# MSPM0G110X register map
Vendor: Texas Instruments; File version: This preliminary header file does not have a version number - build date: 2023-02-21 16:25:48
CPU: CM0 r0p1, little endian, MPU, no FPU, 3 interrupt priority bits
Registers are 32-bit, read-write, reset 0x0 unless marked. A register's access mark holds for its fields unless they carry their own. Offsets are from the block's base; [hi:lo] are bit positions; {n}, {i} and the like mark numbered series.

## CPUSS — CPUSSMMR
Base 0x40400000
0x10E0 EVT_MODE ro — Event Mode
  [1:0] EVT_MODE_INT_CFG — Event line mode select
    0=EVT_MODE_INT_CFG_DISABLE (DISABLE); 1=EVT_MODE_INT_CFG_SOFTWARE (SOFTWARE); 2=EVT_MODE_INT_CFG_HARDWARE (HARDWARE)
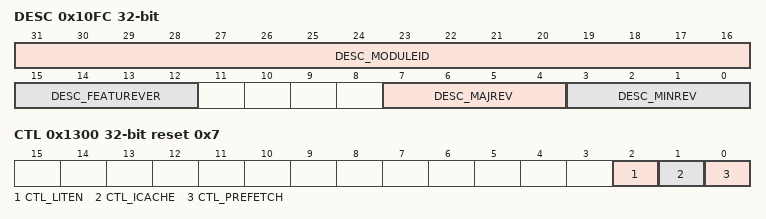
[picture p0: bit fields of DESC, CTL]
0x10FC DESC ro — Module Description
  [31:16] DESC_MODULEID — Module identification contains a unique peripheral identification number. The assignments are maintained in a central database for all of the platform modules to ensure uniqueness.
  [15:12] DESC_FEATUREVER — Feature Set for the module *instance*
  [7:4] DESC_MAJREV — Major rev of the IP
  [3:0] DESC_MINREV — Minor rev of the IP
0x1100 INT_GROUP0_IIDX ro — Interrupt index
  [7:0] INT_GROUP0_IIDX_STAT — Interrupt index status
    0=INT_GROUP0_IIDX_STAT_NO_INTR (NO_INTR); {v}=INT_GROUP0_IIDX_STAT_INT{v-1} (INT{v-1}) (v=1..8)
0x1108 INT_GROUP0_IMASK ro reset 0xFF — Interrupt mask
  [7:0] INT_GROUP0_IMASK_INT — Masks the corresponding interrupt
    0=INT_GROUP0_IMASK_INT_CLR (CLR); 1=INT_GROUP0_IMASK_INT_SET (SET)
0x1110 INT_GROUP0_RIS ro — Raw interrupt status
  [7:0] INT_GROUP0_RIS_INT — Raw interrupt status for INT
    0=INT_GROUP0_RIS_INT_CLR (CLR); 1=INT_GROUP0_RIS_INT_SET (SET)
0x1118 INT_GROUP0_MIS ro — Masked interrupt status
  [0] INT_GROUP0_MIS_INT — Masked interrupt status for INT0
    0=INT_GROUP0_MIS_INT_CLR (CLR); 1=INT_GROUP0_MIS_INT_SET (SET)
0x1120 INT_GROUP0_ISET wo — Interrupt set
  [0] INT_GROUP0_ISET_INT — Sets INT in RIS register
    0=INT_GROUP0_ISET_INT_NO_EFFECT (NO_EFFECT); 1=INT_GROUP0_ISET_INT_SET (SET)
0x1128 INT_GROUP0_ICLR wo — Interrupt clear
  [0] INT_GROUP0_ICLR_INT — Clears INT in RIS register
    0=INT_GROUP0_ICLR_INT_NO_EFFECT (NO_EFFECT); 1=INT_GROUP0_ICLR_INT_CLR (CLR)
0x1130 INT_GROUP1_IIDX ro — Interrupt index
  [7:0] INT_GROUP1_IIDX_STAT — Interrupt index status
    0=INT_GROUP1_IIDX_STAT_NO_INTR (NO_INTR); {v}=INT_GROUP1_IIDX_STAT_INT{v-1} (INT{v-1}) (v=1..8)
0x1138 INT_GROUP1_IMASK ro reset 0xFF — Interrupt mask
  [7:0] INT_GROUP1_IMASK_INT — Masks the corresponding interrupt
    0=INT_GROUP1_IMASK_INT_CLR (CLR); 1=INT_GROUP1_IMASK_INT_SET (SET)
0x1140 INT_GROUP1_RIS ro — Raw interrupt status
  [0] INT_GROUP1_RIS_INT — Raw interrupt status for INT
    0=INT_GROUP1_RIS_INT_CLR (CLR); 1=INT_GROUP1_RIS_INT_SET (SET)
0x1148 INT_GROUP1_MIS ro — Masked interrupt status
  [0] INT_GROUP1_MIS_INT — Masked interrupt status for INT0
    0=INT_GROUP1_MIS_INT_CLR (CLR); 1=INT_GROUP1_MIS_INT_SET (SET)
0x1150 INT_GROUP1_ISET wo — Interrupt set
  [0] INT_GROUP1_ISET_INT — Sets INT in RIS register
    0=INT_GROUP1_ISET_INT_NO_EFFECT (NO_EFFECT); 1=INT_GROUP1_ISET_INT_SET (SET)
0x1158 INT_GROUP1_ICLR wo — Interrupt clear
  [0] INT_GROUP1_ICLR_INT — Clears INT in RIS register
    0=INT_GROUP1_ICLR_INT_NO_EFFECT (NO_EFFECT); 1=INT_GROUP1_ICLR_INT_CLR (CLR)
0x1300 CTL reset 0x7 — Prefetch/Cache control
  [2] CTL_LITEN — Literal caching and prefetch enable. This bit is a subset of ICACHE/PREFETCH bit i.e. literal caching or literal prefetching will only happen if ICACHE or PREFETCH bits have been set respectively When enabled, the cache and prefetcher structures inside CPUSS will cache and prefetch literals When disabled, the cache and prefetcher structures inside CPUSS will not cache and prefetch literals
    0=CTL_LITEN_DISABLE (DISABLE); 1=CTL_LITEN_ENABLE (ENABLE)
  [1] CTL_ICACHE — Used to enable/disable Instruction caching on flash access.
    0=CTL_ICACHE_DISABLE (DISABLE); 1=CTL_ICACHE_ENABLE (ENABLE)
  [0] CTL_PREFETCH — Used to enable/disable instruction prefetch to Flash.
    0=CTL_PREFETCH_DISABLE (DISABLE); 1=CTL_PREFETCH_ENABLE (ENABLE)
